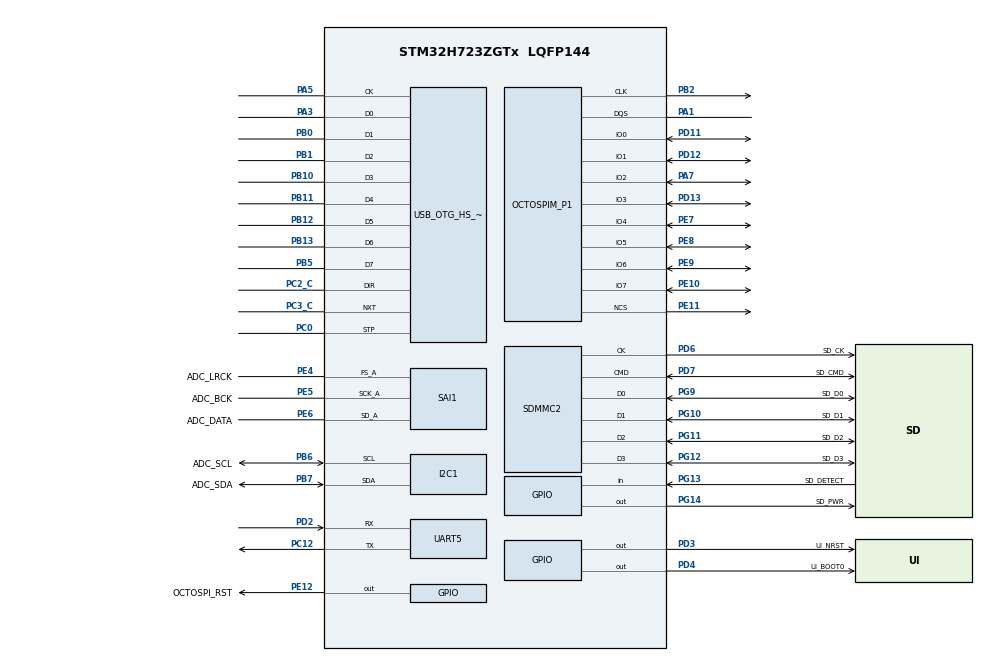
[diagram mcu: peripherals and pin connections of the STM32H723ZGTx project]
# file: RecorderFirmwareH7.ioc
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CORTEX_M7.AccessPermission_S-Cortex_Memory_Protection_Unit_Region1_Settings_S=MPU_REGION_FULL_ACCESS
CORTEX_M7.BaseAddress_S-Cortex_Memory_Protection_Unit_Region1_Settings_S=0x90000000
CORTEX_M7.CPU_DCache=Enabled
CORTEX_M7.CPU_ICache=Enabled
CORTEX_M7.DisableExec_S-Cortex_Memory_Protection_Unit_Region1_Settings_S=MPU_INSTRUCTION_ACCESS_DISABLE
CORTEX_M7.Enable_S-Cortex_Memory_Protection_Unit_Region1_Settings_S=MPU_REGION_ENABLE
CORTEX_M7.IsBufferable_S-Cortex_Memory_Protection_Unit_Region1_Settings_S=MPU_ACCESS_BUFFERABLE
CORTEX_M7.IsCacheable_S-Cortex_Memory_Protection_Unit_Region1_Settings_S=MPU_ACCESS_CACHEABLE
CORTEX_M7.Size_S-Cortex_Memory_Protection_Unit_Region1_Settings_S=MPU_REGION_SIZE_16MB
CORTEX_M7.TypeExtField_S-Cortex_Memory_Protection_Unit_Region1_Settings_S=MPU_TEX_LEVEL1
CORTEX_M7.default_mode_Activation=1
Dma.Request0=SAI1_A
Dma.SAI1_A.0.Direction=DMA_PERIPH_TO_MEMORY
Dma.SAI1_A.0.EventEnable=DISABLE
Dma.SAI1_A.0.FIFOMode=DMA_FIFOMODE_DISABLE
Dma.SAI1_A.0.Instance=DMA1_Stream0
Dma.SAI1_A.0.MemDataAlignment=DMA_MDATAALIGN_WORD
Dma.SAI1_A.0.MemInc=DMA_MINC_ENABLE
Dma.SAI1_A.0.Mode=DMA_CIRCULAR
Dma.SAI1_A.0.PeriphDataAlignment=DMA_PDATAALIGN_WORD
Dma.SAI1_A.0.PeriphInc=DMA_PINC_DISABLE
Dma.SAI1_A.0.Polarity=HAL_DMAMUX_REQ_GEN_RISING
Dma.SAI1_A.0.Priority=DMA_PRIORITY_LOW
Dma.SAI1_A.0.RequestNumber=1
Dma.SAI1_A.0.SignalID=NONE
Dma.SAI1_A.0.SyncEnable=DISABLE
Dma.SAI1_A.0.SyncPolarity=HAL_DMAMUX_SYNC_NO_EVENT
Dma.SAI1_A.0.SyncRequestNumber=1
Dma.SAI1_A.0.SyncSignalID=NONE
I2C1.Timing=0x10B0DCFB
Mcu.Family=STM32H7
Mcu.Name=STM32H723ZGTx
Mcu.Package=LQFP144
NVIC.DMA1_Stream0_IRQn=true\:0\:0\:false\:false\:true\:false\:true\:true
NVIC.PriorityGroup=NVIC_PRIORITYGROUP_4
PA1.Mode=OCTOSPI2_Port1_DQS
PA1.Signal=OCTOSPIM_P1_DQS
PA13(JTMS/SWDIO).Mode=Serial_Wire
PA13(JTMS/SWDIO).Signal=DEBUG_JTMS-SWDIO
PA14(JTCK/SWCLK).Mode=Serial_Wire
PA14(JTCK/SWCLK).Signal=DEBUG_JTCK-SWCLK
PA3.Mode=Device_HS
PA3.Signal=USB_OTG_HS_ULPI_D0
PA5.Mode=Device_HS
PA5.Signal=USB_OTG_HS_ULPI_CK
PA7.Mode=OCTOSPI2_IOL_Port1L
PA7.Signal=OCTOSPIM_P1_IO2
PB0.Mode=Device_HS
PB0.Signal=USB_OTG_HS_ULPI_D1
PB1.Mode=Device_HS
PB1.Signal=USB_OTG_HS_ULPI_D2
PB10.Mode=Device_HS
PB10.Signal=USB_OTG_HS_ULPI_D3
PB11.Mode=Device_HS
PB11.Signal=USB_OTG_HS_ULPI_D4
PB12.Mode=Device_HS
PB12.Signal=USB_OTG_HS_ULPI_D5
PB13.Mode=Device_HS
PB13.Signal=USB_OTG_HS_ULPI_D6
PB2.Mode=O2_P1_CLK
PB2.Signal=OCTOSPIM_P1_CLK
PB5.Mode=Device_HS
PB5.Signal=USB_OTG_HS_ULPI_D7
PB6.GPIO_Label=ADC_SCL
PB6.Mode=I2C
PB6.Signal=I2C1_SCL
PB7.GPIO_Label=ADC_SDA
PB7.Mode=I2C
PB7.Signal=I2C1_SDA
PC0.Mode=Device_HS
PC0.Signal=USB_OTG_HS_ULPI_STP
PC12.Mode=Asynchronous
PC12.Signal=UART5_TX
PC2_C.Mode=Device_HS
PC2_C.Signal=USB_OTG_HS_ULPI_DIR
PC3_C.Mode=Device_HS
PC3_C.Signal=USB_OTG_HS_ULPI_NXT
PD11.Mode=OCTOSPI2_IOL_Port1L
PD11.Signal=OCTOSPIM_P1_IO0
PD12.Mode=OCTOSPI2_IOL_Port1L
PD12.Signal=OCTOSPIM_P1_IO1
PD13.Mode=OCTOSPI2_IOL_Port1L
PD13.Signal=OCTOSPIM_P1_IO3
PD2.Mode=Asynchronous
PD2.Signal=UART5_RX
PD3.GPIO_Label=UI_NRST
PD3.Signal=GPIO_Output
PD4.GPIO_Label=UI_BOOT0
PD4.Signal=GPIO_Output
PD6.GPIO_Label=SD_CK
PD6.Mode=SD_4_bits_Wide_bus
PD6.Signal=SDMMC2_CK
PD7.GPIO_Label=SD_CMD
PD7.Mode=SD_4_bits_Wide_bus
PD7.Signal=SDMMC2_CMD
PE10.Mode=OCTOSPI2_IOH_Port1H
PE10.Signal=OCTOSPIM_P1_IO7
PE11.Mode=OCTOSPI2_Port1_NCS
PE11.Signal=OCTOSPIM_P1_NCS
PE12.GPIO_Label=OCTOSPI_RST
PE12.Signal=GPIO_Output
PE4.GPIO_Label=ADC_LRCK
PE4.Mode=SAI_A_AsyncSlave
PE4.Signal=SAI1_FS_A
PE5.GPIO_Label=ADC_BCK
PE5.Mode=SAI_A_AsyncSlave
PE5.Signal=SAI1_SCK_A
PE6.GPIO_Label=ADC_DATA
PE6.Mode=SAI_A_AsyncSlave
PE6.Signal=SAI1_SD_A
PE7.Mode=OCTOSPI2_IOH_Port1H
PE7.Signal=OCTOSPIM_P1_IO4
PE8.Mode=OCTOSPI2_IOH_Port1H
PE8.Signal=OCTOSPIM_P1_IO5
PE9.Mode=OCTOSPI2_IOH_Port1H
PE9.Signal=OCTOSPIM_P1_IO6
PG10.GPIO_Label=SD_D1
PG10.Mode=SD_4_bits_Wide_bus
PG10.Signal=SDMMC2_D1
PG11.GPIO_Label=SD_D2
PG11.Mode=SD_4_bits_Wide_bus
PG11.Signal=SDMMC2_D2
PG12.GPIO_Label=SD_D3
PG12.Mode=SD_4_bits_Wide_bus
PG12.Signal=SDMMC2_D3
PG13.GPIO_Label=SD_DETECT
PG13.Signal=GPIO_Input
PG14.GPIO_Label=SD_PWR
PG14.Signal=GPIO_Output
PG9.GPIO_Label=SD_D0
PG9.Mode=SD_4_bits_Wide_bus
PG9.Signal=SDMMC2_D0
PH0-OSC_IN.Mode=HSE-External-Oscillator
PH0-OSC_IN.Signal=RCC_OSC_IN
PH1-OSC_OUT.Mode=HSE-External-Oscillator
PH1-OSC_OUT.Signal=RCC_OSC_OUT
ProjectManager.HeapSize=0x200
ProjectManager.StackSize=0x400
ProjectManager.TargetToolchain=CMake
RCC.ADCFreq_Value=32250000
RCC.APB1Freq_Value=96000000
RCC.APB2Freq_Value=96000000
RCC.APB3Freq_Value=96000000
RCC.APB4Freq_Value=96000000
RCC.CortexFreq_Value=192000000
RCC.D1PPRE=RCC_APB3_DIV2
RCC.D2PPRE1=RCC_APB1_DIV2
RCC.D2PPRE2=RCC_APB2_DIV2
RCC.D3PPRE=RCC_APB4_DIV2
RCC.DIVM1=4
RCC.DIVN1=48
RCC.DIVP1=1
RCC.HCLKFreq_Value=192000000
RCC.HSE_VALUE=16000000
RCC.PLL2FRACN=0
RCC.PLL3FRACN=0
RCC.PLLFRACN=0
RCC.SYSCLKFreq_VALUE=192000000
RCC.SYSCLKSource=RCC_SYSCLKSOURCE_PLLCLK
RCC.USBFreq_Value=96000000
SAI1.ActiveFrameLength-SAI_A_AsyncSlave=128
SAI1.ClockStrobing-SAI_A_AsyncSlave=SAI_CLOCKSTROBING_RISINGEDGE
SAI1.DataSize-SAI_A_AsyncSlave=SAI_DATASIZE_32
SAI1.FIFOThreshold-SAI_A_AsyncSlave=SAI_FIFOTHRESHOLD_HF
SAI1.FSPolarity-SAI_A_AsyncSlave=SAI_FS_ACTIVE_HIGH
SAI1.FrameLength-SAI_A_AsyncSlave=256
SAI1.Instance-SAI_A_AsyncSlave=SAI$Index_Block_A
SAI1.SlotActive-SAI_A_AsyncSlave=0x0000FFFF
SAI1.SlotNumber-SAI_A_AsyncSlave=8
SAI1.VirtualMode-SAI_A_AsyncSlave=VM_SLAVE
SAI1.VirtualSlotActive-SAI_A_AsyncSlave=SAI_SLOTACTIVE_ALL
USB_OTG_HS.VirtualMode-Device_HS=Device_HS
VP_MEMORYMAP_VS_MEMORYMAP.Mode=CurAppReg
VP_OCTOSPI2_VS_octo.Mode=octo_mode
board=custom

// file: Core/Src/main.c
/* USER CODE BEGIN Header */
/**
  ******************************************************************************
  * @file           : main.c
  * @brief          : Main program body
  ******************************************************************************
  * @attention
  *
  * Copyright (c) 2026 STMicroelectronics.
  * All rights reserved.
  *
  * This software is licensed under terms that can be found in the LICENSE file
  * in the root directory of this software component.
  * If no LICENSE file comes with this software, it is provided AS-IS.
  *
  ******************************************************************************
  */
/* USER CODE END Header */
#include "main.h"

/* USER CODE BEGIN Includes */
#include "psram.h"

/* USER CODE END Includes */

I2C_HandleTypeDef hi2c1;

OSPI_HandleTypeDef hospi2;

SAI_HandleTypeDef hsai_BlockA1;
DMA_HandleTypeDef hdma_sai1_a;

SD_HandleTypeDef hsd2;

UART_HandleTypeDef huart5;

PCD_HandleTypeDef hpcd_USB_OTG_HS;

/* USER CODE BEGIN PV */
/* Inspect in the debugger after boot */
volatile int psram_status;
volatile uint32_t psram_errors;

/* USER CODE END PV */

void SystemClock_Config(void);
static void MPU_Config(void);
static void MX_GPIO_Init(void);
static void MX_DMA_Init(void);
static void MX_I2C1_Init(void);
static void MX_SAI1_Init(void);
static void MX_OCTOSPI2_Init(void);
static void MX_UART5_Init(void);
static void MX_USB_OTG_HS_PCD_Init(void);
static void MX_SDMMC2_SD_Init(void);

int main(void)
{

  /* MPU Configuration--------------------------------------------------------*/
  MPU_Config();

  /* Enable the CPU Cache */

  /* Enable I-Cache---------------------------------------------------------*/
  SCB_EnableICache();

  /* Enable D-Cache---------------------------------------------------------*/
  SCB_EnableDCache();

  /* MCU Configuration--------------------------------------------------------*/

  /* Reset of all peripherals, Initializes the Flash interface and the Systick. */
  HAL_Init();

  /* Configure the system clock */
  SystemClock_Config();

  /* Initialize all configured peripherals */
  MX_GPIO_Init();
  MX_DMA_Init();
  MX_I2C1_Init();
  MX_SAI1_Init();
  MX_OCTOSPI2_Init();
  MX_UART5_Init();
  MX_USB_OTG_HS_PCD_Init();
  MX_SDMMC2_SD_Init();
  /* USER CODE BEGIN 2 */
  if(PSRAM_Init(&hospi1) != PSRAM_OK) {
    Error_Handler();
  }
  psram_errors = PSRAM_Test();

  /* USER CODE END 2 */

  /* Infinite loop */
  while (1)
  {

  }
}

void SystemClock_Config(void)
{
  RCC_OscInitTypeDef RCC_OscInitStruct = {0};
  RCC_ClkInitTypeDef RCC_ClkInitStruct = {0};

  /** Supply configuration update enable
  */
  HAL_PWREx_ConfigSupply(PWR_LDO_SUPPLY);

  /** Configure the main internal regulator output voltage
  */
  __HAL_PWR_VOLTAGESCALING_CONFIG(PWR_REGULATOR_VOLTAGE_SCALE1);

  while(!__HAL_PWR_GET_FLAG(PWR_FLAG_VOSRDY)) {}

  /** Initializes the RCC Oscillators according to the specified parameters
  * in the RCC_OscInitTypeDef structure.
  */
  RCC_OscInitStruct.OscillatorType = RCC_OSCILLATORTYPE_HSE;
  RCC_OscInitStruct.HSEState = RCC_HSE_ON;
  RCC_OscInitStruct.PLL.PLLState = RCC_PLL_ON;
  RCC_OscInitStruct.PLL.PLLSource = RCC_PLLSOURCE_HSE;
  RCC_OscInitStruct.PLL.PLLM = 4;
  RCC_OscInitStruct.PLL.PLLN = 48;
  RCC_OscInitStruct.PLL.PLLP = 1;
  RCC_OscInitStruct.PLL.PLLQ = 2;
  RCC_OscInitStruct.PLL.PLLR = 2;
  RCC_OscInitStruct.PLL.PLLRGE = RCC_PLL1VCIRANGE_2;
  RCC_OscInitStruct.PLL.PLLVCOSEL = RCC_PLL1VCOWIDE;
  RCC_OscInitStruct.PLL.PLLFRACN = 0;
  if (HAL_RCC_OscConfig(&RCC_OscInitStruct) != HAL_OK)
  {
    Error_Handler();
  }

  /** Initializes the CPU, AHB and APB buses clocks
  */
  RCC_ClkInitStruct.ClockType = RCC_CLOCKTYPE_HCLK|RCC_CLOCKTYPE_SYSCLK
                              |RCC_CLOCKTYPE_PCLK1|RCC_CLOCKTYPE_PCLK2
                              |RCC_CLOCKTYPE_D3PCLK1|RCC_CLOCKTYPE_D1PCLK1;
  RCC_ClkInitStruct.SYSCLKSource = RCC_SYSCLKSOURCE_PLLCLK;
  RCC_ClkInitStruct.SYSCLKDivider = RCC_SYSCLK_DIV1;
  RCC_ClkInitStruct.AHBCLKDivider = RCC_HCLK_DIV1;
  RCC_ClkInitStruct.APB3CLKDivider = RCC_APB3_DIV2;
  RCC_ClkInitStruct.APB1CLKDivider = RCC_APB1_DIV2;
  RCC_ClkInitStruct.APB2CLKDivider = RCC_APB2_DIV2;
  RCC_ClkInitStruct.APB4CLKDivider = RCC_APB4_DIV2;

  if (HAL_RCC_ClockConfig(&RCC_ClkInitStruct, FLASH_LATENCY_2) != HAL_OK)
  {
    Error_Handler();
  }
}

static void MX_I2C1_Init(void)
{

  hi2c1.Instance = I2C1;
  hi2c1.Init.Timing = 0x10B0DCFB;
  hi2c1.Init.OwnAddress1 = 0;
  hi2c1.Init.AddressingMode = I2C_ADDRESSINGMODE_7BIT;
  hi2c1.Init.DualAddressMode = I2C_DUALADDRESS_DISABLE;
  hi2c1.Init.OwnAddress2 = 0;
  hi2c1.Init.OwnAddress2Masks = I2C_OA2_NOMASK;
  hi2c1.Init.GeneralCallMode = I2C_GENERALCALL_DISABLE;
  hi2c1.Init.NoStretchMode = I2C_NOSTRETCH_DISABLE;
  if (HAL_I2C_Init(&hi2c1) != HAL_OK)
  {
    Error_Handler();
  }

  /** Configure Analogue filter
  */
  if (HAL_I2CEx_ConfigAnalogFilter(&hi2c1, I2C_ANALOGFILTER_ENABLE) != HAL_OK)
  {
    Error_Handler();
  }

  /** Configure Digital filter
  */
  if (HAL_I2CEx_ConfigDigitalFilter(&hi2c1, 0) != HAL_OK)
  {
    Error_Handler();
  }

}

static void MX_OCTOSPI2_Init(void)
{

  OSPIM_CfgTypeDef sOspiManagerCfg = {0};

  /* OCTOSPI2 parameter configuration*/
  hospi2.Instance = OCTOSPI2;
  hospi2.Init.FifoThreshold = 1;
  hospi2.Init.DualQuad = HAL_OSPI_DUALQUAD_DISABLE;
  hospi2.Init.MemoryType = HAL_OSPI_MEMTYPE_MICRON;
  hospi2.Init.DeviceSize = 32;
  hospi2.Init.ChipSelectHighTime = 1;
  hospi2.Init.FreeRunningClock = HAL_OSPI_FREERUNCLK_DISABLE;
  hospi2.Init.ClockMode = HAL_OSPI_CLOCK_MODE_0;
  hospi2.Init.WrapSize = HAL_OSPI_WRAP_NOT_SUPPORTED;
  hospi2.Init.ClockPrescaler = 1;
  hospi2.Init.SampleShifting = HAL_OSPI_SAMPLE_SHIFTING_NONE;
  hospi2.Init.DelayHoldQuarterCycle = HAL_OSPI_DHQC_DISABLE;
  hospi2.Init.ChipSelectBoundary = 0;
  hospi2.Init.DelayBlockBypass = HAL_OSPI_DELAY_BLOCK_BYPASSED;
  hospi2.Init.MaxTran = 0;
  hospi2.Init.Refresh = 0;
  if (HAL_OSPI_Init(&hospi2) != HAL_OK)
  {
    Error_Handler();
  }
  sOspiManagerCfg.ClkPort = 1;
  sOspiManagerCfg.DQSPort = 1;
  sOspiManagerCfg.NCSPort = 1;
  sOspiManagerCfg.IOLowPort = HAL_OSPIM_IOPORT_1_LOW;
  sOspiManagerCfg.IOHighPort = HAL_OSPIM_IOPORT_1_HIGH;
  if (HAL_OSPIM_Config(&hospi2, &sOspiManagerCfg, HAL_OSPI_TIMEOUT_DEFAULT_VALUE) != HAL_OK)
  {
    Error_Handler();
  }

}

static void MX_SAI1_Init(void)
{

  hsai_BlockA1.Instance = SAI1_Block_A;
  hsai_BlockA1.Init.Protocol = SAI_FREE_PROTOCOL;
  hsai_BlockA1.Init.AudioMode = SAI_MODESLAVE_RX;
  hsai_BlockA1.Init.DataSize = SAI_DATASIZE_32;
  hsai_BlockA1.Init.FirstBit = SAI_FIRSTBIT_MSB;
  hsai_BlockA1.Init.ClockStrobing = SAI_CLOCKSTROBING_RISINGEDGE;
  hsai_BlockA1.Init.Synchro = SAI_ASYNCHRONOUS;
  hsai_BlockA1.Init.OutputDrive = SAI_OUTPUTDRIVE_DISABLE;
  hsai_BlockA1.Init.FIFOThreshold = SAI_FIFOTHRESHOLD_HF;
  hsai_BlockA1.Init.SynchroExt = SAI_SYNCEXT_DISABLE;
  hsai_BlockA1.Init.MonoStereoMode = SAI_STEREOMODE;
  hsai_BlockA1.Init.CompandingMode = SAI_NOCOMPANDING;
  hsai_BlockA1.Init.TriState = SAI_OUTPUT_NOTRELEASED;
  hsai_BlockA1.Init.PdmInit.Activation = DISABLE;
  hsai_BlockA1.Init.PdmInit.MicPairsNbr = 0;
  hsai_BlockA1.Init.PdmInit.ClockEnable = SAI_PDM_CLOCK1_ENABLE;
  hsai_BlockA1.FrameInit.FrameLength = 256;
  hsai_BlockA1.FrameInit.ActiveFrameLength = 128;
  hsai_BlockA1.FrameInit.FSDefinition = SAI_FS_STARTFRAME;
  hsai_BlockA1.FrameInit.FSPolarity = SAI_FS_ACTIVE_HIGH;
  hsai_BlockA1.FrameInit.FSOffset = SAI_FS_FIRSTBIT;
  hsai_BlockA1.SlotInit.FirstBitOffset = 0;
  hsai_BlockA1.SlotInit.SlotSize = SAI_SLOTSIZE_DATASIZE;
  hsai_BlockA1.SlotInit.SlotNumber = 8;
  hsai_BlockA1.SlotInit.SlotActive = 0x0000FFFF;
  if (HAL_SAI_Init(&hsai_BlockA1) != HAL_OK)
  {
    Error_Handler();
  }

}

static void MX_SDMMC2_SD_Init(void)
{

  hsd2.Instance = SDMMC2;
  hsd2.Init.ClockEdge = SDMMC_CLOCK_EDGE_RISING;
  hsd2.Init.ClockPowerSave = SDMMC_CLOCK_POWER_SAVE_DISABLE;
  hsd2.Init.BusWide = SDMMC_BUS_WIDE_4B;
  hsd2.Init.HardwareFlowControl = SDMMC_HARDWARE_FLOW_CONTROL_DISABLE;
  hsd2.Init.ClockDiv = 0;
  if (HAL_SD_Init(&hsd2) != HAL_OK)
  {
    Error_Handler();
  }

}

static void MX_UART5_Init(void)
{

  huart5.Instance = UART5;
  huart5.Init.BaudRate = 115200;
  huart5.Init.WordLength = UART_WORDLENGTH_8B;
  huart5.Init.StopBits = UART_STOPBITS_1;
  huart5.Init.Parity = UART_PARITY_NONE;
  huart5.Init.Mode = UART_MODE_TX_RX;
  huart5.Init.HwFlowCtl = UART_HWCONTROL_NONE;
  huart5.Init.OverSampling = UART_OVERSAMPLING_16;
  huart5.Init.OneBitSampling = UART_ONE_BIT_SAMPLE_DISABLE;
  huart5.Init.ClockPrescaler = UART_PRESCALER_DIV1;
  huart5.AdvancedInit.AdvFeatureInit = UART_ADVFEATURE_NO_INIT;
  if (HAL_UART_Init(&huart5) != HAL_OK)
  {
    Error_Handler();
  }
  if (HAL_UARTEx_SetTxFifoThreshold(&huart5, UART_TXFIFO_THRESHOLD_1_8) != HAL_OK)
  {
    Error_Handler();
  }
  if (HAL_UARTEx_SetRxFifoThreshold(&huart5, UART_RXFIFO_THRESHOLD_1_8) != HAL_OK)
  {
    Error_Handler();
  }
  if (HAL_UARTEx_DisableFifoMode(&huart5) != HAL_OK)
  {
    Error_Handler();
  }

}

static void MX_USB_OTG_HS_PCD_Init(void)
{

  hpcd_USB_OTG_HS.Instance = USB_OTG_HS;
  hpcd_USB_OTG_HS.Init.dev_endpoints = 9;
  hpcd_USB_OTG_HS.Init.speed = PCD_SPEED_HIGH;
  hpcd_USB_OTG_HS.Init.dma_enable = DISABLE;
  hpcd_USB_OTG_HS.Init.phy_itface = USB_OTG_ULPI_PHY;
  hpcd_USB_OTG_HS.Init.Sof_enable = DISABLE;
  hpcd_USB_OTG_HS.Init.low_power_enable = DISABLE;
  hpcd_USB_OTG_HS.Init.lpm_enable = DISABLE;
  hpcd_USB_OTG_HS.Init.vbus_sensing_enable = DISABLE;
  hpcd_USB_OTG_HS.Init.use_dedicated_ep1 = DISABLE;
  hpcd_USB_OTG_HS.Init.use_external_vbus = DISABLE;
  if (HAL_PCD_Init(&hpcd_USB_OTG_HS) != HAL_OK)
  {
    Error_Handler();
  }

}

static void MX_DMA_Init(void)
{

  /* DMA controller clock enable */
  __HAL_RCC_DMA1_CLK_ENABLE();

  /* DMA interrupt init */
  /* DMA1_Stream0_IRQn interrupt configuration */
  HAL_NVIC_SetPriority(DMA1_Stream0_IRQn, 0, 0);
  HAL_NVIC_EnableIRQ(DMA1_Stream0_IRQn);

}

static void MX_GPIO_Init(void)
{
  GPIO_InitTypeDef GPIO_InitStruct = {0};

  /* GPIO Ports Clock Enable */
  __HAL_RCC_GPIOE_CLK_ENABLE();
  __HAL_RCC_GPIOH_CLK_ENABLE();
  __HAL_RCC_GPIOC_CLK_ENABLE();
  __HAL_RCC_GPIOA_CLK_ENABLE();
  __HAL_RCC_GPIOB_CLK_ENABLE();
  __HAL_RCC_GPIOD_CLK_ENABLE();
  __HAL_RCC_GPIOG_CLK_ENABLE();

  /*Configure GPIO pin Output Level */
  HAL_GPIO_WritePin(OCTOSPI_RST_GPIO_Port, OCTOSPI_RST_Pin, GPIO_PIN_RESET);

  /*Configure GPIO pin Output Level */
  HAL_GPIO_WritePin(GPIOD, UI_NRST_Pin|UI_BOOT0_Pin, GPIO_PIN_RESET);

  /*Configure GPIO pin : OCTOSPI_RST_Pin */
  GPIO_InitStruct.Pin = OCTOSPI_RST_Pin;
  GPIO_InitStruct.Mode = GPIO_MODE_OUTPUT_PP;
  GPIO_InitStruct.Pull = GPIO_NOPULL;
  GPIO_InitStruct.Speed = GPIO_SPEED_FREQ_LOW;
  HAL_GPIO_Init(OCTOSPI_RST_GPIO_Port, &GPIO_InitStruct);

  /*Configure GPIO pins : UI_NRST_Pin UI_BOOT0_Pin */
  GPIO_InitStruct.Pin = UI_NRST_Pin|UI_BOOT0_Pin;
  GPIO_InitStruct.Mode = GPIO_MODE_OUTPUT_PP;
  GPIO_InitStruct.Pull = GPIO_NOPULL;
  GPIO_InitStruct.Speed = GPIO_SPEED_FREQ_LOW;
  HAL_GPIO_Init(GPIOD, &GPIO_InitStruct);

}

 /* MPU Configuration */

void MPU_Config(void)
{
  MPU_Region_InitTypeDef MPU_InitStruct = {0};

  /* Disables the MPU */
  HAL_MPU_Disable();

  /** Initializes and configures the Region and the memory to be protected
  */
  MPU_InitStruct.Enable = MPU_REGION_ENABLE;
  MPU_InitStruct.Number = MPU_REGION_NUMBER0;
  MPU_InitStruct.BaseAddress = 0x0;
  MPU_InitStruct.Size = MPU_REGION_SIZE_4GB;
  MPU_InitStruct.SubRegionDisable = 0x87;
  MPU_InitStruct.TypeExtField = MPU_TEX_LEVEL0;
  MPU_InitStruct.AccessPermission = MPU_REGION_NO_ACCESS;
  MPU_InitStruct.DisableExec = MPU_INSTRUCTION_ACCESS_DISABLE;
  MPU_InitStruct.IsShareable = MPU_ACCESS_SHAREABLE;
  MPU_InitStruct.IsCacheable = MPU_ACCESS_NOT_CACHEABLE;
  MPU_InitStruct.IsBufferable = MPU_ACCESS_NOT_BUFFERABLE;

  HAL_MPU_ConfigRegion(&MPU_InitStruct);

  /** Initializes and configures the Region and the memory to be protected
  */
  MPU_InitStruct.Number = MPU_REGION_NUMBER1;
  MPU_InitStruct.BaseAddress = 0x90000000;
  MPU_InitStruct.Size = MPU_REGION_SIZE_16MB;
  MPU_InitStruct.SubRegionDisable = 0x0;
  MPU_InitStruct.TypeExtField = MPU_TEX_LEVEL1;
  MPU_InitStruct.AccessPermission = MPU_REGION_FULL_ACCESS;
  MPU_InitStruct.IsShareable = MPU_ACCESS_NOT_SHAREABLE;
  MPU_InitStruct.IsCacheable = MPU_ACCESS_CACHEABLE;
  MPU_InitStruct.IsBufferable = MPU_ACCESS_BUFFERABLE;

  HAL_MPU_ConfigRegion(&MPU_InitStruct);
  /* Enables the MPU */
  HAL_MPU_Enable(MPU_PRIVILEGED_DEFAULT);

}

void Error_Handler(void)
{
  __disable_irq();
  while (1)
  {
  }
}
